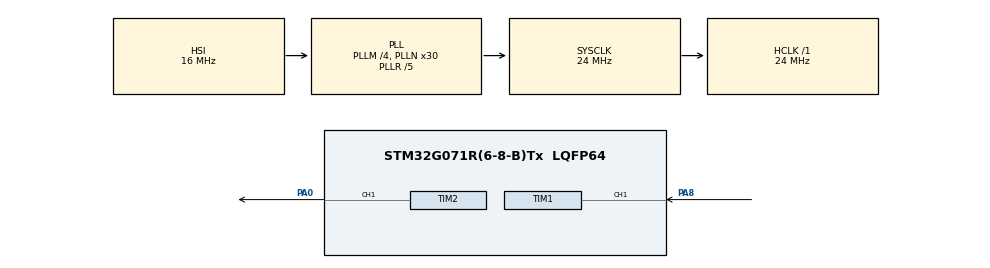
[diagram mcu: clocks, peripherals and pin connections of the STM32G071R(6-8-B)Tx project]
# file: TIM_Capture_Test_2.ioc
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Mcu.Family=STM32G0
Mcu.Name=STM32G071R(6-8-B)Tx
Mcu.Package=LQFP64
NVIC.TIM1_CC_IRQn=true\:0\:0\:false\:false\:true\:true\:true
PA0.Signal=S_TIM2_CH1
PA8.Signal=S_TIM1_CH1
ProjectManager.HeapSize=0x200
ProjectManager.StackSize=0x400
ProjectManager.TargetToolchain=MDK-ARM V5.27
RCC.ADCFreq_Value=24000000
RCC.AHBFreq_Value=24000000
RCC.CodegenConfigPeriph=false
RCC.CortexFreq_Value=24000000
RCC.EXTERNAL_CLOCK_VALUE=48000
RCC.HCLKFreq_Value=24000000
RCC.HSE_VALUE=8000000
RCC.HSI_VALUE=16000000
RCC.LSE_VALUE=32768
RCC.PLLM=RCC_PLLM_DIV4
RCC.PLLN=30
RCC.PLLP=RCC_PLLP_DIV10
RCC.PLLQ=RCC_PLLQ_DIV5
RCC.PLLR=RCC_PLLR_DIV5
RCC.SYSCLKFreq_VALUE=24000000
RCC.SYSCLKSource=RCC_SYSCLKSOURCE_PLLCLK
RCC.VCOOutputFreq_Value=120000000
SH.S_TIM1_CH1.0=TIM1_CH1,Input_Capture1_from_TI1
SH.S_TIM2_CH1.0=TIM2_CH1,PWM Generation1 CH1
TIM1.Channel-Input_Capture1_from_TI1=TIM_CHANNEL_1
TIM1.Period=0xFFFF
TIM1.Prescaler=4095
TIM2.Channel-PWM\ Generation1\ CH1=TIM_CHANNEL_1
TIM2.Period=10000
TIM2.Prescaler=127
TIM2.Pulse-PWM\ Generation1\ CH1=5000
VP_SYS_VS_DBSignals.Mode=DisableDeadBatterySignals
board=custom

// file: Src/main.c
#include "main.h"
TIM_HandleTypeDef htim1;
TIM_HandleTypeDef htim2;
void SystemClock_Config(void);
static void MX_GPIO_Init(void);
static void MX_TIM1_Init(void);
static void MX_TIM2_Init(void);

uint32_t uwIC2Value1 = 0;			//触发捕获的第一个计数值
uint32_t uwIC2Value2 = 0;			//触发捕获的第二个计数值
uint32_t uwDiffCapture = 0;		//触发捕获的时间差
uint16_t uhCaptureIndex = 0;	//捕获指标：标明第一次捕获还是第二次捕获
double uwFrequency = 0;			//uint32_t频率值

int main(void)
{
  HAL_Init();
  SystemClock_Config();
  MX_GPIO_Init();
  MX_TIM1_Init();
  MX_TIM2_Init();

	HAL_TIM_PWM_Start(&htim2,TIM_CHANNEL_1);
	if(HAL_TIM_IC_Start_IT(&htim1, TIM_CHANNEL_1) != HAL_OK)
    Error_Handler();  //打开失败
  while (1)
  {

  }
}

void SystemClock_Config(void)
{
  RCC_OscInitTypeDef RCC_OscInitStruct = {0};
  RCC_ClkInitTypeDef RCC_ClkInitStruct = {0};

  /** Initializes the RCC Oscillators according to the specified parameters
  * in the RCC_OscInitTypeDef structure.
  */
  RCC_OscInitStruct.OscillatorType = RCC_OSCILLATORTYPE_HSI;
  RCC_OscInitStruct.HSIState = RCC_HSI_ON;
  RCC_OscInitStruct.HSIDiv = RCC_HSI_DIV1;
  RCC_OscInitStruct.HSICalibrationValue = RCC_HSICALIBRATION_DEFAULT;
  RCC_OscInitStruct.PLL.PLLState = RCC_PLL_ON;
  RCC_OscInitStruct.PLL.PLLSource = RCC_PLLSOURCE_HSI;
  RCC_OscInitStruct.PLL.PLLM = RCC_PLLM_DIV4;
  RCC_OscInitStruct.PLL.PLLN = 30;
  RCC_OscInitStruct.PLL.PLLP = RCC_PLLP_DIV10;
  RCC_OscInitStruct.PLL.PLLQ = RCC_PLLQ_DIV5;
  RCC_OscInitStruct.PLL.PLLR = RCC_PLLR_DIV5;
  if (HAL_RCC_OscConfig(&RCC_OscInitStruct) != HAL_OK)
  {
    Error_Handler();
  }
  /** Initializes the CPU, AHB and APB buses clocks
  */
  RCC_ClkInitStruct.ClockType = RCC_CLOCKTYPE_HCLK|RCC_CLOCKTYPE_SYSCLK
                              |RCC_CLOCKTYPE_PCLK1;
  RCC_ClkInitStruct.SYSCLKSource = RCC_SYSCLKSOURCE_PLLCLK;
  RCC_ClkInitStruct.AHBCLKDivider = RCC_SYSCLK_DIV1;
  RCC_ClkInitStruct.APB1CLKDivider = RCC_HCLK_DIV1;

  if (HAL_RCC_ClockConfig(&RCC_ClkInitStruct, FLASH_LATENCY_0) != HAL_OK)
  {
    Error_Handler();
  }
}

static void MX_TIM1_Init(void)
{

  TIM_MasterConfigTypeDef sMasterConfig = {0};
  TIM_IC_InitTypeDef sConfigIC = {0};
  TIM_BreakDeadTimeConfigTypeDef sBreakDeadTimeConfig = {0};

  htim1.Instance = TIM1;
  htim1.Init.Prescaler = 4095;
  htim1.Init.CounterMode = TIM_COUNTERMODE_UP;
  htim1.Init.Period = 0xFFFF;
  htim1.Init.ClockDivision = TIM_CLOCKDIVISION_DIV1;
  htim1.Init.RepetitionCounter = 0;
  htim1.Init.AutoReloadPreload = TIM_AUTORELOAD_PRELOAD_DISABLE;
  if (HAL_TIM_IC_Init(&htim1) != HAL_OK)
  {
    Error_Handler();
  }
  sMasterConfig.MasterOutputTrigger = TIM_TRGO_RESET;
  sMasterConfig.MasterOutputTrigger2 = TIM_TRGO2_RESET;
  sMasterConfig.MasterSlaveMode = TIM_MASTERSLAVEMODE_DISABLE;
  if (HAL_TIMEx_MasterConfigSynchronization(&htim1, &sMasterConfig) != HAL_OK)
  {
    Error_Handler();
  }
  sConfigIC.ICPolarity = TIM_INPUTCHANNELPOLARITY_RISING;
  sConfigIC.ICSelection = TIM_ICSELECTION_DIRECTTI;
  sConfigIC.ICPrescaler = TIM_ICPSC_DIV1;
  sConfigIC.ICFilter = 0;
  if (HAL_TIM_IC_ConfigChannel(&htim1, &sConfigIC, TIM_CHANNEL_1) != HAL_OK)
  {
    Error_Handler();
  }
  sBreakDeadTimeConfig.BreakAFMode = TIM_BREAK_AFMODE_INPUT;
  sBreakDeadTimeConfig.Break2AFMode = TIM_BREAK_AFMODE_INPUT;
  if (HAL_TIMEx_ConfigBreakDeadTime(&htim1, &sBreakDeadTimeConfig) != HAL_OK)
  {
    Error_Handler();
  }

}

static void MX_TIM2_Init(void)
{

  TIM_MasterConfigTypeDef sMasterConfig = {0};
  TIM_OC_InitTypeDef sConfigOC = {0};

  htim2.Instance = TIM2;
  htim2.Init.Prescaler = 127;
  htim2.Init.CounterMode = TIM_COUNTERMODE_UP;
  htim2.Init.Period = 10000;
  htim2.Init.ClockDivision = TIM_CLOCKDIVISION_DIV1;
  htim2.Init.AutoReloadPreload = TIM_AUTORELOAD_PRELOAD_DISABLE;
  if (HAL_TIM_PWM_Init(&htim2) != HAL_OK)
  {
    Error_Handler();
  }
  sMasterConfig.MasterOutputTrigger = TIM_TRGO_RESET;
  sMasterConfig.MasterSlaveMode = TIM_MASTERSLAVEMODE_DISABLE;
  if (HAL_TIMEx_MasterConfigSynchronization(&htim2, &sMasterConfig) != HAL_OK)
  {
    Error_Handler();
  }
  sConfigOC.OCMode = TIM_OCMODE_PWM1;
  sConfigOC.Pulse = 5000;
  sConfigOC.OCPolarity = TIM_OCPOLARITY_HIGH;
  sConfigOC.OCFastMode = TIM_OCFAST_DISABLE;
  if (HAL_TIM_PWM_ConfigChannel(&htim2, &sConfigOC, TIM_CHANNEL_1) != HAL_OK)
  {
    Error_Handler();
  }
  HAL_TIM_MspPostInit(&htim2);

}

static void MX_GPIO_Init(void)
{

  /* GPIO Ports Clock Enable */
  __HAL_RCC_GPIOA_CLK_ENABLE();

}

/* USER CODE BEGIN 4 */
void HAL_TIM_IC_CaptureCallback(TIM_HandleTypeDef *htim)
{
  if (htim->Channel == HAL_TIM_ACTIVE_CHANNEL_1)
  {
    if(uhCaptureIndex == 0)		/* 第一次捕获 */
    {
      uwIC2Value1 = HAL_TIM_ReadCapturedValue(htim, TIM_CHANNEL_1);  /* 获取计数值 */
      uhCaptureIndex = 1;
    }
    else if(uhCaptureIndex == 1)      /* 第二次捕获 */
    {
      uwIC2Value2 = HAL_TIM_ReadCapturedValue(htim, TIM_CHANNEL_1);		/* 获取计数值 */
      if (uwIC2Value2 > uwIC2Value1)		/* 计算两次捕获计数器值之差 */
      {
        uwDiffCapture = (uwIC2Value2 - uwIC2Value1);
      }
      else if (uwIC2Value2 < uwIC2Value1)
      {
        /*0xFFFF 是最大的TIM1_CCRx寄存器值，转了一圈回来了Value2+max+1 - Value1 */
        uwDiffCapture = ((0xFFFF - uwIC2Value1) + uwIC2Value2) + 1;
      }
      else        /*如果捕获值相等,就代表超过了最高的频率测量值（计数器还没反应过来已经捕获两次了）*/
        Error_Handler();
      /* 频率计算: 在这个例子中，定时器1时钟源是APB1Clk */
      uwFrequency = HAL_RCC_GetPCLK1Freq() * 1.000 / uwDiffCapture  / 4096; //4096是定时器1分频值
      uhCaptureIndex = 0;
    }
  }
}
/* USER CODE END 4 */

void Error_Handler(void)
{
  __disable_irq();
  while (1)
  {
  }
}

/************************ (C) COPYRIGHT STMicroelectronics *****END OF FILE****/
